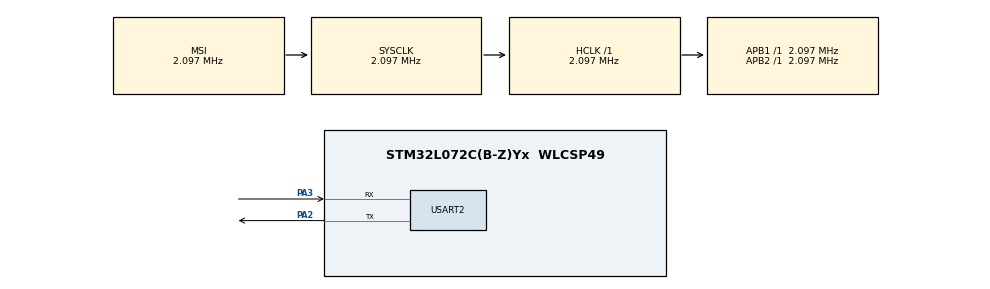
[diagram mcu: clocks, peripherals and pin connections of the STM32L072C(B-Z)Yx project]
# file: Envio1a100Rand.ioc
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Mcu.Family=STM32L0
Mcu.Name=STM32L072C(B-Z)Yx
Mcu.Package=WLCSP49
PA2.Mode=Asynchronous
PA2.Signal=USART2_TX
PA3.Mode=Asynchronous
PA3.Signal=USART2_RX
ProjectManager.HeapSize=0x200
ProjectManager.StackSize=0x400
ProjectManager.TargetToolchain=STM32CubeIDE
RCC.AHBFreq_Value=2097000
RCC.APB1Freq_Value=2097000
RCC.APB1TimFreq_Value=2097000
RCC.APB2Freq_Value=2097000
RCC.APB2TimFreq_Value=2097000
RCC.HSE_VALUE=8000000
RCC.HSI16_VALUE=16000000
RCC.HSI48_VALUE=48000000
RCC.HSI_VALUE=16000000
RCC.LSE_VALUE=32768
RCC.MSI_VALUE=2097000
RCC.SYSCLKFreq_VALUE=2097000
RCC.VCOOutputFreq_Value=48000000
USART2.VirtualMode-Asynchronous=VM_ASYNC
board=custom

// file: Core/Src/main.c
/* USER CODE BEGIN Header */
/**
  ******************************************************************************
  * @file           : main.c
  * @brief          : Main program body
  ******************************************************************************
  * @attention
  *
  * Copyright (c) 2025 STMicroelectronics.
  * All rights reserved.
  *
  * This software is licensed under terms that can be found in the LICENSE file
  * in the root directory of this software component.
  * If no LICENSE file comes with this software, it is provided AS-IS.
  *
  ******************************************************************************
  */
/* USER CODE END Header */
#include "main.h"

/* USER CODE BEGIN Includes */
#include <stdio.h>    // Para sprintf y la redirección de printf
#include <stdlib.h>   // Para rand() y srand()
#include <time.h>     // Para time()

/* USER CODE END Includes */

UART_HandleTypeDef huart2;

void SystemClock_Config(void);
static void MX_GPIO_Init(void);
static void MX_USART2_UART_Init(void);
/* USER CODE BEGIN PFP */
int __io_putchar(int ch);

/* USER CODE END PFP */

/* USER CODE BEGIN 0 */
int __io_putchar(int ch)
{
    // Asegúrate de que el handle de tu UART sea el correcto (huart2 en este caso)
    HAL_UART_Transmit(&huart2, (uint8_t *)&ch, 1, HAL_MAX_DELAY);
    return ch;
}

/* USER CODE END 0 */

int main(void)
{

  /* MCU Configuration--------------------------------------------------------*/

  /* Reset of all peripherals, Initializes the Flash interface and the Systick. */
  HAL_Init();

  /* Configure the system clock */
  SystemClock_Config();

  /* Initialize all configured peripherals */
  MX_GPIO_Init();
  MX_USART2_UART_Init();
  /* USER CODE BEGIN 2 */
  srand(HAL_GetTick()); // Usa el tick del sistema como semilla

  /* USER CODE END 2 */

  /* Infinite loop */
  while (1)
    {

    /* USER CODE BEGIN 3 */
      int randomNumber = rand() % 100 + 1; // Genera un número entre 1 y 100
      int randomNumber2 = rand() % 100 + 1; // Genera un número entre 1 y 100
      int randomNumber3 = rand() % 100 + 1; // Genera un número entre 1 y 100

      char msg[50]; // Buffer para construir el mensaje
      // Formatea el mensaje: "Número aleatorio: XX\r\n"
      sprintf(msg, "Numeros aleatorios: %d, %d, %d\r\n", randomNumber, randomNumber2, randomNumber3);

      // Envía el mensaje por UART.
      // Usamos HAL_UART_Transmit directamente o printf si redirigiste __io_putchar.
      // Si usaste la redirección de printf:
      printf("%s", msg);

      // Si NO usaste la redirección de printf, usa esto en su lugar:
      // HAL_UART_Transmit(&huart2, (uint8_t *)msg, strlen(msg), HAL_MAX_DELAY);
      // Necesitarías #include <string.h> para strlen

      HAL_Delay(100); // Espera 0,1 segundo (100 milisegundos)
    }
  /* USER CODE END 3 */
}

void SystemClock_Config(void)
{
  RCC_OscInitTypeDef RCC_OscInitStruct = {0};
  RCC_ClkInitTypeDef RCC_ClkInitStruct = {0};
  RCC_PeriphCLKInitTypeDef PeriphClkInit = {0};

  /** Configure the main internal regulator output voltage
  */
  __HAL_PWR_VOLTAGESCALING_CONFIG(PWR_REGULATOR_VOLTAGE_SCALE1);

  /** Initializes the RCC Oscillators according to the specified parameters
  * in the RCC_OscInitTypeDef structure.
  */
  RCC_OscInitStruct.OscillatorType = RCC_OSCILLATORTYPE_MSI;
  RCC_OscInitStruct.MSIState = RCC_MSI_ON;
  RCC_OscInitStruct.MSICalibrationValue = 0;
  RCC_OscInitStruct.MSIClockRange = RCC_MSIRANGE_5;
  RCC_OscInitStruct.PLL.PLLState = RCC_PLL_NONE;
  if (HAL_RCC_OscConfig(&RCC_OscInitStruct) != HAL_OK)
  {
    Error_Handler();
  }

  /** Initializes the CPU, AHB and APB buses clocks
  */
  RCC_ClkInitStruct.ClockType = RCC_CLOCKTYPE_HCLK|RCC_CLOCKTYPE_SYSCLK
                              |RCC_CLOCKTYPE_PCLK1|RCC_CLOCKTYPE_PCLK2;
  RCC_ClkInitStruct.SYSCLKSource = RCC_SYSCLKSOURCE_MSI;
  RCC_ClkInitStruct.AHBCLKDivider = RCC_SYSCLK_DIV1;
  RCC_ClkInitStruct.APB1CLKDivider = RCC_HCLK_DIV1;
  RCC_ClkInitStruct.APB2CLKDivider = RCC_HCLK_DIV1;

  if (HAL_RCC_ClockConfig(&RCC_ClkInitStruct, FLASH_LATENCY_0) != HAL_OK)
  {
    Error_Handler();
  }
  PeriphClkInit.PeriphClockSelection = RCC_PERIPHCLK_USART2;
  PeriphClkInit.Usart2ClockSelection = RCC_USART2CLKSOURCE_PCLK1;
  if (HAL_RCCEx_PeriphCLKConfig(&PeriphClkInit) != HAL_OK)
  {
    Error_Handler();
  }
}

static void MX_USART2_UART_Init(void)
{

  huart2.Instance = USART2;
  huart2.Init.BaudRate = 115200;
  huart2.Init.WordLength = UART_WORDLENGTH_8B;
  huart2.Init.StopBits = UART_STOPBITS_1;
  huart2.Init.Parity = UART_PARITY_NONE;
  huart2.Init.Mode = UART_MODE_TX_RX;
  huart2.Init.HwFlowCtl = UART_HWCONTROL_NONE;
  huart2.Init.OverSampling = UART_OVERSAMPLING_16;
  huart2.Init.OneBitSampling = UART_ONE_BIT_SAMPLE_DISABLE;
  huart2.AdvancedInit.AdvFeatureInit = UART_ADVFEATURE_NO_INIT;
  if (HAL_UART_Init(&huart2) != HAL_OK)
  {
    Error_Handler();
  }

}

static void MX_GPIO_Init(void)
{

  /* GPIO Ports Clock Enable */
  __HAL_RCC_GPIOA_CLK_ENABLE();

}

void Error_Handler(void)
{
  __disable_irq();
  while (1)
  {
  }
}
